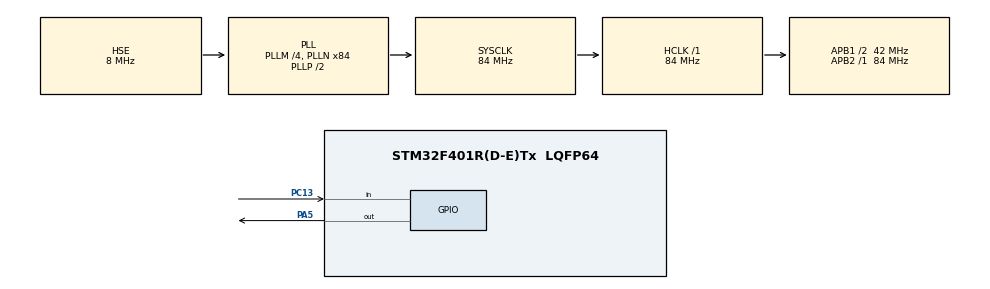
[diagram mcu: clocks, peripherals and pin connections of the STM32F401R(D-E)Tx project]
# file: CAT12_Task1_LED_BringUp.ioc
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Mcu.Family=STM32F4
Mcu.Name=STM32F401R(D-E)Tx
Mcu.Package=LQFP64
NVIC.PriorityGroup=NVIC_PRIORITYGROUP_4
PA13.Mode=Serial_Wire
PA13.Signal=SYS_JTMS-SWDIO
PA14.Mode=Serial_Wire
PA14.Signal=SYS_JTCK-SWCLK
PA5.Signal=GPIO_Output
PC13-ANTI_TAMP.GPIO_PuPd=GPIO_PULLUP
PC13-ANTI_TAMP.Signal=GPIO_Input
PH0\ -\ OSC_IN.Mode=HSE-External-Clock-Source
PH0\ -\ OSC_IN.Signal=RCC_OSC_IN
PH1\ -\ OSC_OUT.Mode=HSE-External-Clock-Source
PH1\ -\ OSC_OUT.Signal=RCC_OSC_OUT
ProjectManager.HeapSize=0x200
ProjectManager.StackSize=0x400
ProjectManager.TargetToolchain=STM32CubeIDE
RCC.48MHZClocksFreq_Value=42000000
RCC.AHBFreq_Value=84000000
RCC.APB1CLKDivider=RCC_HCLK_DIV2
RCC.APB1Freq_Value=42000000
RCC.APB1TimFreq_Value=84000000
RCC.APB2Freq_Value=84000000
RCC.APB2TimFreq_Value=84000000
RCC.CortexFreq_Value=84000000
RCC.HCLKFreq_Value=84000000
RCC.HSE_VALUE=8000000
RCC.HSI_VALUE=16000000
RCC.LSE_VALUE=32768
RCC.PLLM=4
RCC.PLLN=84
RCC.PLLSourceVirtual=RCC_PLLSOURCE_HSE
RCC.SYSCLKFreq_VALUE=84000000
RCC.SYSCLKSource=RCC_SYSCLKSOURCE_PLLCLK
RCC.VCOOutputFreq_Value=168000000
board=custom

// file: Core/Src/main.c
/* USER CODE BEGIN Header */
/**
  ******************************************************************************
  * @file           : main.c
  * @brief          : CAT 12 - Task 1 : NUCLEO-F401RE on-board LED bring-up
  *                    LD2 blinks at 1 Hz; blinks fast if SYSCLK is not the expected 84 MHz.
  ******************************************************************************
  * @attention
  *
  * Copyright (c) 2026 STMicroelectronics.
  * All rights reserved.
  *
  * This software is licensed under terms that can be found in the LICENSE file
  * in the root directory of this software component.
  * If no LICENSE file comes with this software, it is provided AS-IS.
  *
  ******************************************************************************
  */
/* USER CODE END Header */
#include "main.h"

/* USER CODE BEGIN PD */
/* NUCLEO-F401RE on-board parts (UM1724)
 *   LD2 (green LED) : PA5,  ACTIVE-HIGH
 *   B1  (blue key)  : PC13, ACTIVE-LOW (external pull-up on the board)
 * Clock: 8 MHz from the ST-LINK MCO (HSE bypass) -> PLL M=4 N=84 P=2 -> 84 MHz */
#define LED_PORT          GPIOA
#define LED_PIN           GPIO_PIN_5
#define BTN_PORT          GPIOC
#define BTN_PIN           GPIO_PIN_13
#define EXPECTED_SYSCLK   84000000UL

#define BLINK_MS          500U    /* normal: 1 Hz blink (500 ms ON, 500 ms OFF)     */
#define BLINK_FAULT_MS    100U    /* fast blink = clock is NOT 84 MHz (check CubeMX) */
/* USER CODE END PD */

/* USER CODE BEGIN PV */
uint32_t sysclk_hz = 0;          /* watch in Live Expressions: should read 84000000 */
static uint32_t last_toggle = 0;
static uint32_t blink_ms = BLINK_MS;
/* USER CODE END PV */

void SystemClock_Config(void);
static void MX_GPIO_Init(void);

int main(void)
{

  /* MCU Configuration--------------------------------------------------------*/

  /* Reset of all peripherals, Initializes the Flash interface and the Systick. */
  HAL_Init();

  /* Configure the system clock */
  SystemClock_Config();

  /* Initialize all configured peripherals */
  MX_GPIO_Init();
  /* USER CODE BEGIN 2 */
  /* Verify the clock tree that CubeMX configured */
  sysclk_hz = HAL_RCC_GetSysClockFreq();
  blink_ms  = (sysclk_hz == EXPECTED_SYSCLK) ? BLINK_MS : BLINK_FAULT_MS;
  HAL_GPIO_WritePin(LED_PORT, LED_PIN, GPIO_PIN_RESET);
  /* USER CODE END 2 */

  /* Infinite loop */
  while (1)
  {

    /* USER CODE BEGIN 3 */
    /* Fixed-interval blink using the 1 ms SysTick time base (no HAL_Delay) */
    if ((HAL_GetTick() - last_toggle) >= blink_ms)
    {
      last_toggle = HAL_GetTick();
      HAL_GPIO_TogglePin(LED_PORT, LED_PIN);
    }
  }
  /* USER CODE END 3 */
}

void SystemClock_Config(void)
{
  RCC_OscInitTypeDef RCC_OscInitStruct = {0};
  RCC_ClkInitTypeDef RCC_ClkInitStruct = {0};

  /** Configure the main internal regulator output voltage
  */
  __HAL_RCC_PWR_CLK_ENABLE();
  __HAL_PWR_VOLTAGESCALING_CONFIG(PWR_REGULATOR_VOLTAGE_SCALE2);

  /** Initializes the RCC Oscillators according to the specified parameters
  * in the RCC_OscInitTypeDef structure.
  */
  RCC_OscInitStruct.OscillatorType = RCC_OSCILLATORTYPE_HSE;
  RCC_OscInitStruct.HSEState = RCC_HSE_BYPASS;
  RCC_OscInitStruct.PLL.PLLState = RCC_PLL_ON;
  RCC_OscInitStruct.PLL.PLLSource = RCC_PLLSOURCE_HSE;
  RCC_OscInitStruct.PLL.PLLM = 4;
  RCC_OscInitStruct.PLL.PLLN = 84;
  RCC_OscInitStruct.PLL.PLLP = RCC_PLLP_DIV2;
  RCC_OscInitStruct.PLL.PLLQ = 4;
  if (HAL_RCC_OscConfig(&RCC_OscInitStruct) != HAL_OK)
  {
    Error_Handler();
  }

  /** Initializes the CPU, AHB and APB buses clocks
  */
  RCC_ClkInitStruct.ClockType = RCC_CLOCKTYPE_HCLK|RCC_CLOCKTYPE_SYSCLK
                              |RCC_CLOCKTYPE_PCLK1|RCC_CLOCKTYPE_PCLK2;
  RCC_ClkInitStruct.SYSCLKSource = RCC_SYSCLKSOURCE_PLLCLK;
  RCC_ClkInitStruct.AHBCLKDivider = RCC_SYSCLK_DIV1;
  RCC_ClkInitStruct.APB1CLKDivider = RCC_HCLK_DIV2;
  RCC_ClkInitStruct.APB2CLKDivider = RCC_HCLK_DIV1;

  if (HAL_RCC_ClockConfig(&RCC_ClkInitStruct, FLASH_LATENCY_2) != HAL_OK)
  {
    Error_Handler();
  }
}

static void MX_GPIO_Init(void)
{
  GPIO_InitTypeDef GPIO_InitStruct = {0};

  /* GPIO Ports Clock Enable */
  __HAL_RCC_GPIOC_CLK_ENABLE();
  __HAL_RCC_GPIOH_CLK_ENABLE();
  __HAL_RCC_GPIOA_CLK_ENABLE();

  /*Configure GPIO pin Output Level */
  HAL_GPIO_WritePin(GPIOA, GPIO_PIN_5, GPIO_PIN_RESET);

  /*Configure GPIO pin : PC13 */
  GPIO_InitStruct.Pin = GPIO_PIN_13;
  GPIO_InitStruct.Mode = GPIO_MODE_INPUT;
  GPIO_InitStruct.Pull = GPIO_PULLUP;
  HAL_GPIO_Init(GPIOC, &GPIO_InitStruct);

  /*Configure GPIO pin : PA5 */
  GPIO_InitStruct.Pin = GPIO_PIN_5;
  GPIO_InitStruct.Mode = GPIO_MODE_OUTPUT_PP;
  GPIO_InitStruct.Pull = GPIO_NOPULL;
  GPIO_InitStruct.Speed = GPIO_SPEED_FREQ_LOW;
  HAL_GPIO_Init(GPIOA, &GPIO_InitStruct);

}

void Error_Handler(void)
{
  __disable_irq();
  while (1)
  {
  }
}
